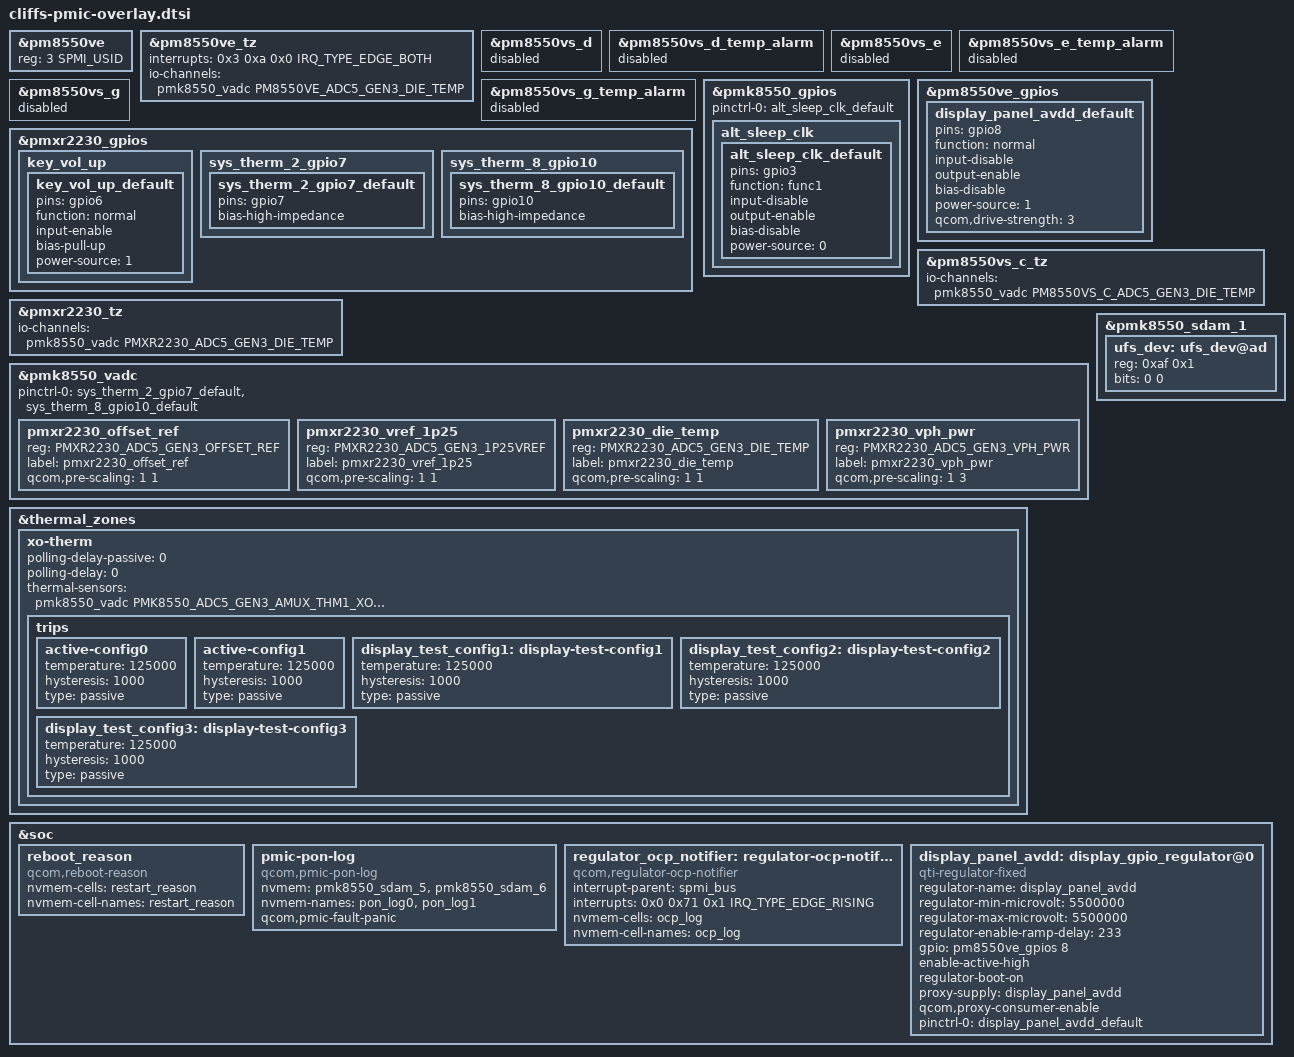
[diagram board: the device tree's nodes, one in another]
#include <dt-bindings/gpio/gpio.h>
#include <dt-bindings/iio/qcom,spmi-adc5-gen3-pmxr2230.h>
#include <dt-bindings/iio/qcom,spmi-adc5-gen3-smb139x.h>
#include <dt-bindings/spmi/spmi.h>

#define PM8550VE_SID  3

#include "pmk8550.dtsi"
#include "pmxr2230.dtsi"
#include "pm8550vs.dtsi"
#include "pm8550ve.dtsi"
#include "pmr735a.dtsi"
#include "pm8010.dtsi"

/* Set SID from 0x8 to 0x3 for pm8550ve */
&pm8550ve {
	reg = <3 SPMI_USID>;
};

&pm8550ve_tz {
	interrupts = <0x3 0xa 0x0 IRQ_TYPE_EDGE_BOTH>;
	io-channels = <&pmk8550_vadc PM8550VE_ADC5_GEN3_DIE_TEMP>;
	io-channel-names = "thermal";
};

&pm8550vs_d {
	status = "disabled";
};

&pm8550vs_d_temp_alarm {
	status = "disabled";
};

&pm8550vs_e {
	status = "disabled";
};

&pm8550vs_e_temp_alarm {
	status = "disabled";
};

&pm8550vs_g {
	status = "disabled";
};

&pm8550vs_g_temp_alarm {
	status = "disabled";
};

&pmxr2230_gpios {
	key_vol_up {
		key_vol_up_default: key_vol_up_default {
			pins = "gpio6";
			function = "normal";
			input-enable;
			bias-pull-up;
			power-source = <1>;
		};
	};

	sys_therm_2_gpio7 {
		sys_therm_2_gpio7_default: sys_therm_2_gpio7_default {
			pins = "gpio7";
			bias-high-impedance;
		};
	};

	sys_therm_8_gpio10 {
		sys_therm_8_gpio10_default: sys_therm_8_gpio10_default {
			pins = "gpio10";
			bias-high-impedance;
		};
	};
};

&pmk8550_gpios {
	pinctrl-0 = <&alt_sleep_clk_default>;
	pinctrl-names = "default";

	alt_sleep_clk {
		alt_sleep_clk_default: alt_sleep_clk_default {
			pins = "gpio3";
			function = "func1";
			input-disable;
			output-enable;
			bias-disable;
			power-source = <0>;
		};
	};
};

&pm8550ve_gpios {
	display_panel_avdd_default: display_panel_avdd_default {
		pins = "gpio8";
		function = "normal";
		input-disable;
		output-enable;
		bias-disable;
		power-source = <1>;
		qcom,drive-strength = <3>;
	};
};

&pm8550vs_c_tz {
	io-channels = <&pmk8550_vadc PM8550VS_C_ADC5_GEN3_DIE_TEMP>;
	io-channel-names = "thermal";
};

&pmxr2230_tz {
	io-channels = <&pmk8550_vadc PMXR2230_ADC5_GEN3_DIE_TEMP>;
	io-channel-names = "thermal";
};

&pmk8550_vadc {
	pinctrl-names = "default";
	pinctrl-0 = <&sys_therm_2_gpio7_default &sys_therm_8_gpio10_default>;

	/delete-node/ pm8550_offset_ref;
	/delete-node/ pm8550_vref_1p25;
	/delete-node/ pm8550_die_temp;
	/delete-node/ pm8550_vph_pwr;

	/delete-node/ pm8550vs_d_die_temp;
	/delete-node/ pm8550vs_e_die_temp;
	/delete-node/ pm8550vs_g_die_temp;

	/* PMXR2230 Channel nodes */
	pmxr2230_offset_ref {
		reg = <PMXR2230_ADC5_GEN3_OFFSET_REF>;
		label = "pmxr2230_offset_ref";
		qcom,pre-scaling = <1 1>;
	};

	pmxr2230_vref_1p25 {
		reg = <PMXR2230_ADC5_GEN3_1P25VREF>;
		label = "pmxr2230_vref_1p25";
		qcom,pre-scaling = <1 1>;
	};

	pmxr2230_die_temp {
		reg = <PMXR2230_ADC5_GEN3_DIE_TEMP>;
		label = "pmxr2230_die_temp";
		qcom,pre-scaling = <1 1>;
	};

	pmxr2230_vph_pwr {
		reg = <PMXR2230_ADC5_GEN3_VPH_PWR>;
		label = "pmxr2230_vph_pwr";
		qcom,pre-scaling = <1 3>;
	};
};

&thermal_zones {
	xo-therm {
		polling-delay-passive = <0>;
		polling-delay = <0>;
		thermal-sensors = <&pmk8550_vadc PMK8550_ADC5_GEN3_AMUX_THM1_XO_THERM_100K_PU>;
		trips {
			active-config0 {
				temperature = <125000>;
				hysteresis = <1000>;
				type = "passive";
			};

			active-config1 {
				temperature = <125000>;
				hysteresis = <1000>;
				type = "passive";
			};

			display_test_config1: display-test-config1 {
				temperature = <125000>;
				hysteresis = <1000>;
				type = "passive";
			};

			display_test_config2: display-test-config2 {
				temperature = <125000>;
				hysteresis = <1000>;
				type = "passive";
			};

			display_test_config3: display-test-config3 {
				temperature = <125000>;
				hysteresis = <1000>;
				type = "passive";
			};
		};
	};
};

&pmk8550_sdam_1 {
	ufs_dev: ufs_dev@ad {
		reg = <0xaf 0x1>;
		bits = <0 0>;
	};
};

&soc {
	reboot_reason {
		compatible = "qcom,reboot-reason";
		nvmem-cells = <&restart_reason>;
		nvmem-cell-names = "restart_reason";
	};

	pmic-pon-log {
		compatible = "qcom,pmic-pon-log";
		nvmem = <&pmk8550_sdam_5>, <&pmk8550_sdam_6>;
		nvmem-names = "pon_log0", "pon_log1";
		qcom,pmic-fault-panic;
	};

	regulator_ocp_notifier: regulator-ocp-notifier {
		compatible = "qcom,regulator-ocp-notifier";
		interrupt-parent = <&spmi_bus>;
		interrupts = <0x0 0x71 0x1 IRQ_TYPE_EDGE_RISING>;
		nvmem-cells = <&ocp_log>;
		nvmem-cell-names = "ocp_log";
	};

	display_panel_avdd: display_gpio_regulator@0 {
		compatible = "qti-regulator-fixed";
		regulator-name = "display_panel_avdd";
		regulator-min-microvolt = <5500000>;
		regulator-max-microvolt = <5500000>;
		regulator-enable-ramp-delay = <233>;
		gpio = <&pm8550ve_gpios 8 0>;
		enable-active-high;
		regulator-boot-on;
		proxy-supply = <&display_panel_avdd>;
		qcom,proxy-consumer-enable;
		pinctrl-names = "default";
		pinctrl-0 = <&display_panel_avdd_default>;
	};
};
